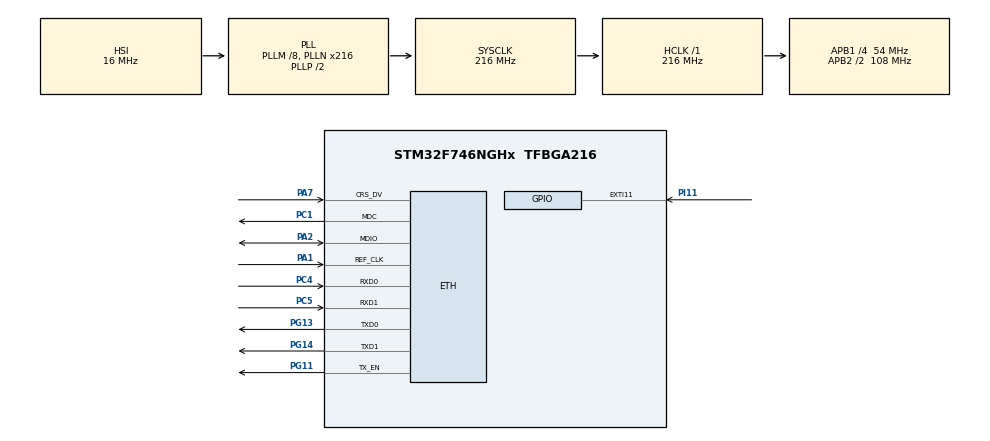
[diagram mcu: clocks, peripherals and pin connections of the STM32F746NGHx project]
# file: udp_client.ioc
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ETH.AutoNegotiation=ETH_AUTONEGOTIATION_ENABLE
ETH.MediaInterface=ETH_MEDIA_INTERFACE_RMII
LWIP.GATEWAY_ADDRESS=192.168.000.001
LWIP.IP_ADDRESS=192.168.000.005
LWIP.LWIP_DHCP=0
LWIP.LWIP_ICMP=0
LWIP.LWIP_NETIF_LINK_CALLBACK=1
LWIP.LWIP_NETIF_LOOPBACK=0
LWIP.LWIP_TCP=0
LWIP.NETMASK_ADDRESS=255.255.255.000
LWIP.Version=v2.0.3_Cube
Mcu.Family=STM32F7
Mcu.Name=STM32F746NGHx
Mcu.Package=TFBGA216
NVIC.PriorityGroup=NVIC_PRIORITYGROUP_4
PA1.Mode=RMII
PA1.Signal=ETH_REF_CLK
PA2.Mode=RMII
PA2.Signal=ETH_MDIO
PA7.Mode=RMII
PA7.Signal=ETH_CRS_DV
PC1.Mode=RMII
PC1.Signal=ETH_MDC
PC4.Mode=RMII
PC4.Signal=ETH_RXD0
PC5.Mode=RMII
PC5.Signal=ETH_RXD1
PG11.Mode=RMII
PG11.Signal=ETH_TX_EN
PG13.Mode=RMII
PG13.Signal=ETH_TXD0
PG14.Mode=RMII
PG14.Signal=ETH_TXD1
PH0/OSC_IN.Mode=HSE-External-Oscillator
PH0/OSC_IN.Signal=RCC_OSC_IN
PH1/OSC_OUT.Mode=HSE-External-Oscillator
PH1/OSC_OUT.Signal=RCC_OSC_OUT
PI11.Signal=GPXTI11
ProjectManager.HeapSize=0x200
ProjectManager.StackSize=0x400
ProjectManager.TargetToolchain=MDK-ARM V5
RCC.AHBFreq_Value=216000000
RCC.APB1CLKDivider=RCC_HCLK_DIV4
RCC.APB1Freq_Value=54000000
RCC.APB1TimFreq_Value=108000000
RCC.APB2CLKDivider=RCC_HCLK_DIV2
RCC.APB2Freq_Value=108000000
RCC.APB2TimFreq_Value=216000000
RCC.CortexFreq_Value=216000000
RCC.HCLKFreq_Value=216000000
RCC.HSE_VALUE=25000000
RCC.HSI_VALUE=16000000
RCC.LSE_VALUE=32768
RCC.PLLM=8
RCC.PLLN=216
RCC.SYSCLKFreq_VALUE=216000000
RCC.SYSCLKSource=RCC_SYSCLKSOURCE_PLLCLK
RCC.USBFreq_Value=216000000
RCC.VCOOutputFreq_Value=432000000
VP_LWIP_VS_Enabled.Mode=Enabled
board=custom

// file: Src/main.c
/* USER CODE BEGIN Header */
/**
  ******************************************************************************
  * @file           : main.c
  * @brief          : Main program body
  ******************************************************************************
  * @attention
  *
  * <h2><center>&copy; Copyright (c) 2021 STMicroelectronics.
  * All rights reserved.</center></h2>
  *
  * This software component is licensed by ST under Ultimate Liberty license
  * SLA0044, the "License"; You may not use this file except in compliance with
  * the License. You may obtain a copy of the License at:
  *                             www.st.com/SLA0044
  *
  ******************************************************************************
  */
/* USER CODE END Header */

#include "main.h"
#include "lwip.h"

/* USER CODE BEGIN Includes */
#include "udp_echoclient.h"
/* USER CODE END Includes */

void SystemClock_Config(void);
static void MX_GPIO_Init(void);
/* USER CODE BEGIN PFP */
extern struct netif gnetif;
/* USER CODE END PFP */

/* USER CODE BEGIN 0 */
uint8_t a ;
/* USER CODE END 0 */

int main(void)
{

  /* MCU Configuration--------------------------------------------------------*/

  /* Reset of all peripherals, Initializes the Flash interface and the Systick. */
  HAL_Init();

  /* Configure the system clock */
  SystemClock_Config();

  /* Initialize all configured peripherals */
  MX_GPIO_Init();
  MX_LWIP_Init();
  /* USER CODE BEGIN 2 */
	udp_echoclient_connect();
  /* USER CODE END 2 */

  /* Infinite loop */
  while (1)
  {
    ethernetif_input(&gnetif);

    /* Handle timeouts */
    sys_check_timeouts();

  }
}

void SystemClock_Config(void)
{
  RCC_OscInitTypeDef RCC_OscInitStruct = {0};
  RCC_ClkInitTypeDef RCC_ClkInitStruct = {0};

  /** Configure the main internal regulator output voltage
  */
  __HAL_RCC_PWR_CLK_ENABLE();
  __HAL_PWR_VOLTAGESCALING_CONFIG(PWR_REGULATOR_VOLTAGE_SCALE1);
  /** Initializes the CPU, AHB and APB busses clocks
  */
  RCC_OscInitStruct.OscillatorType = RCC_OSCILLATORTYPE_HSI;
  RCC_OscInitStruct.HSIState = RCC_HSI_ON;
  RCC_OscInitStruct.HSICalibrationValue = RCC_HSICALIBRATION_DEFAULT;
  RCC_OscInitStruct.PLL.PLLState = RCC_PLL_ON;
  RCC_OscInitStruct.PLL.PLLSource = RCC_PLLSOURCE_HSI;
  RCC_OscInitStruct.PLL.PLLM = 8;
  RCC_OscInitStruct.PLL.PLLN = 216;
  RCC_OscInitStruct.PLL.PLLP = RCC_PLLP_DIV2;
  RCC_OscInitStruct.PLL.PLLQ = 2;
  if (HAL_RCC_OscConfig(&RCC_OscInitStruct) != HAL_OK)
  {
    Error_Handler();
  }
  /** Activate the Over-Drive mode
  */
  if (HAL_PWREx_EnableOverDrive() != HAL_OK)
  {
    Error_Handler();
  }
  /** Initializes the CPU, AHB and APB busses clocks
  */
  RCC_ClkInitStruct.ClockType = RCC_CLOCKTYPE_HCLK|RCC_CLOCKTYPE_SYSCLK
                              |RCC_CLOCKTYPE_PCLK1|RCC_CLOCKTYPE_PCLK2;
  RCC_ClkInitStruct.SYSCLKSource = RCC_SYSCLKSOURCE_PLLCLK;
  RCC_ClkInitStruct.AHBCLKDivider = RCC_SYSCLK_DIV1;
  RCC_ClkInitStruct.APB1CLKDivider = RCC_HCLK_DIV4;
  RCC_ClkInitStruct.APB2CLKDivider = RCC_HCLK_DIV2;

  if (HAL_RCC_ClockConfig(&RCC_ClkInitStruct, FLASH_LATENCY_7) != HAL_OK)
  {
    Error_Handler();
  }
}

static void MX_GPIO_Init(void)
{
  GPIO_InitTypeDef GPIO_InitStruct = {0};

  /* GPIO Ports Clock Enable */
  __HAL_RCC_GPIOG_CLK_ENABLE();
  __HAL_RCC_GPIOI_CLK_ENABLE();
  __HAL_RCC_GPIOH_CLK_ENABLE();
  __HAL_RCC_GPIOC_CLK_ENABLE();
  __HAL_RCC_GPIOA_CLK_ENABLE();

  /*Configure GPIO pin : PI11 */
  GPIO_InitStruct.Pin = GPIO_PIN_11;
  GPIO_InitStruct.Mode = GPIO_MODE_IT_RISING;
  GPIO_InitStruct.Pull = GPIO_NOPULL;
  HAL_GPIO_Init(GPIOI, &GPIO_InitStruct);
	HAL_NVIC_EnableIRQ(EXTI15_10_IRQn);

}

/* USER CODE BEGIN 4 */
void HAL_GPIO_EXTI_Callback(uint16_t GPIO_Pin)
{
	if (GPIO_Pin == GPIO_PIN_11)
  {
     /*connect to tcp server */
     udp_echoclient_send();
  }
}
/* USER CODE END 4 */

void Error_Handler(void)
{
}

/************************ (C) COPYRIGHT STMicroelectronics *****END OF FILE****/
